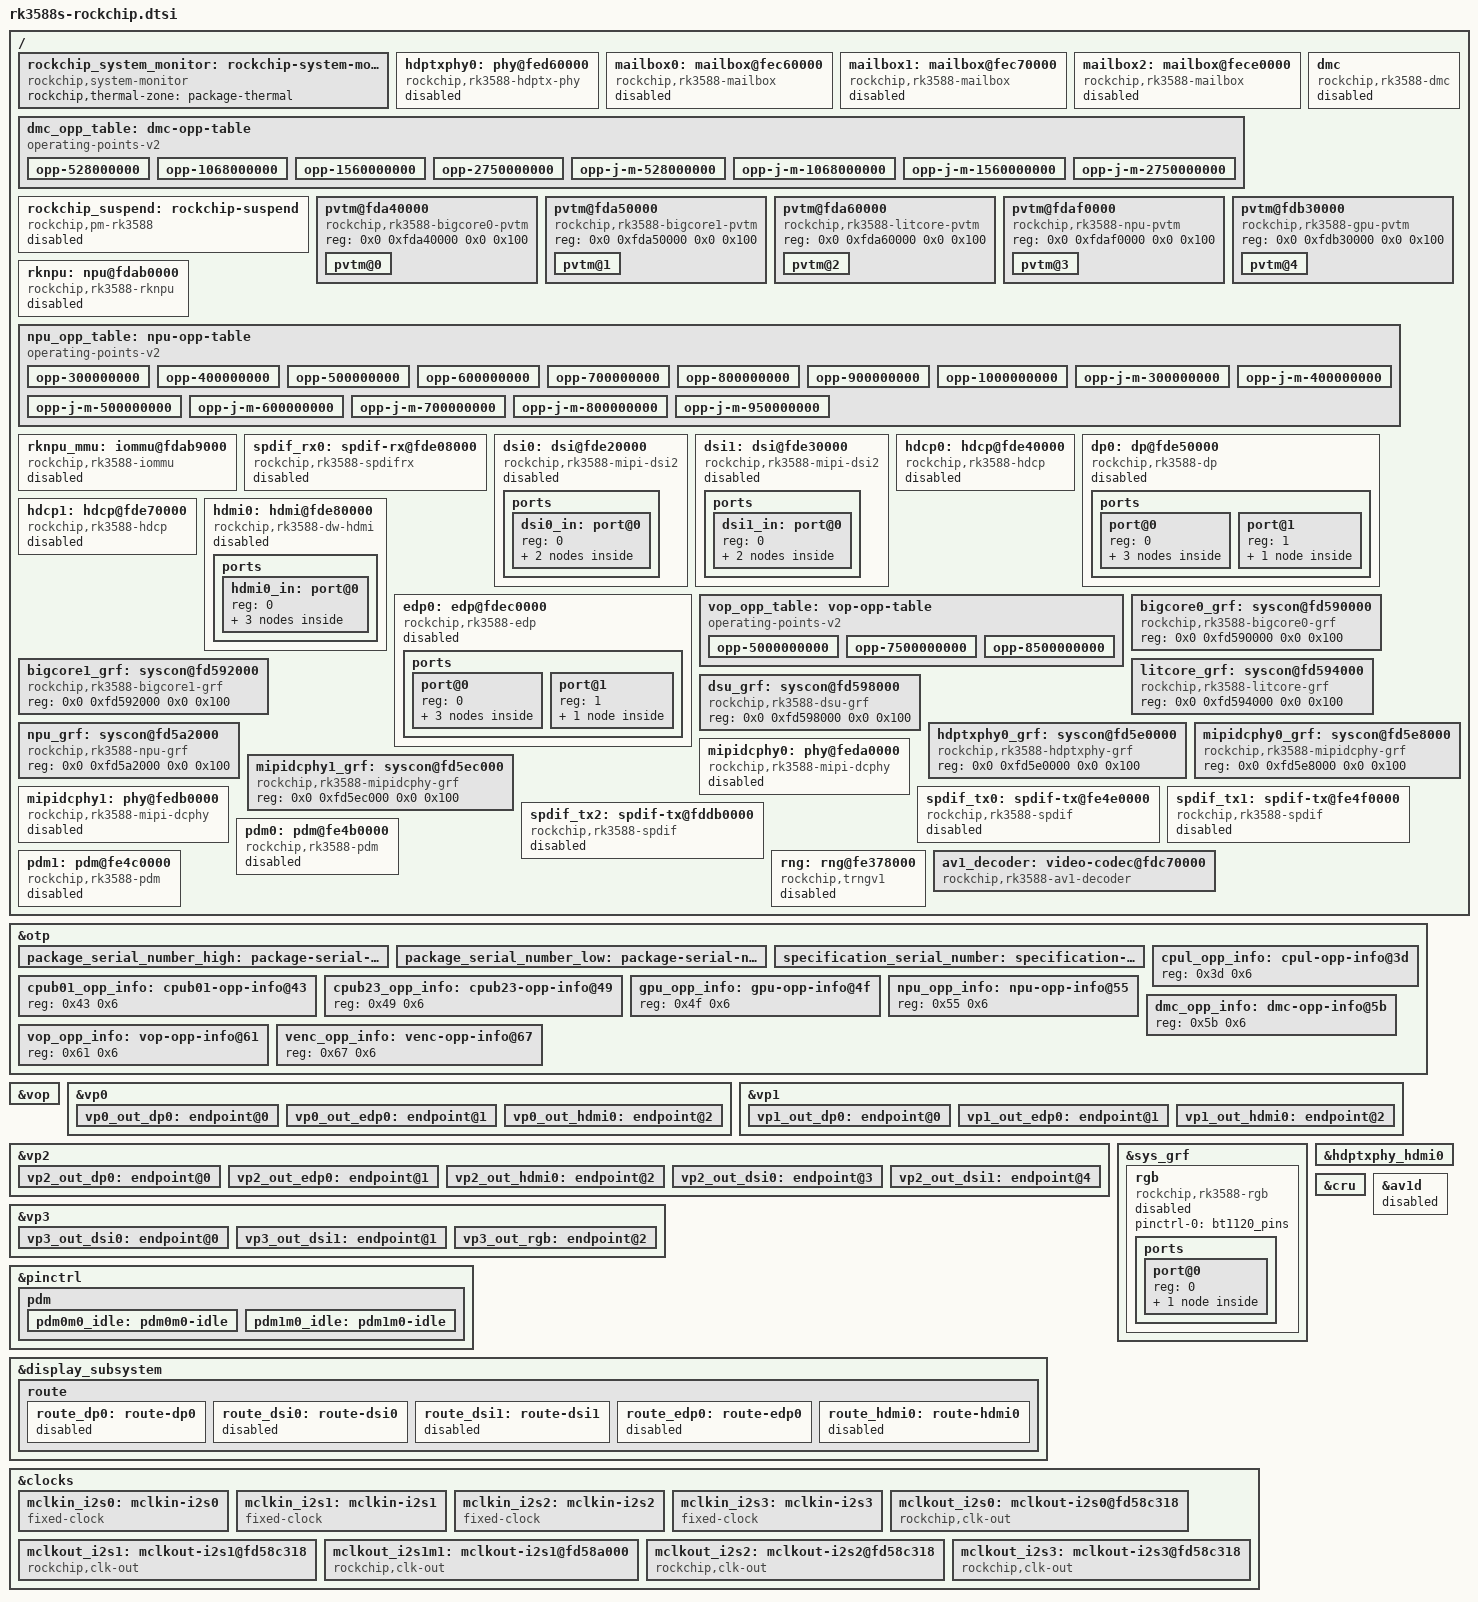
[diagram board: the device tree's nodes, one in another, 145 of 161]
// SPDX-License-Identifier: (GPL-2.0+ OR MIT)

#include <dt-bindings/suspend/rockchip-rk3588.h>
#include <dt-bindings/soc/rockchip-system-status.h>
/ {

  rockchip_system_monitor: rockchip-system-monitor {
    compatible = "rockchip,system-monitor";

    rockchip,thermal-zone = "package-thermal";
  };

  hdptxphy0: phy@fed60000 {
    compatible = "rockchip,rk3588-hdptx-phy";
    reg = <0x0 0xfed60000 0x0 0x2000>;
    clocks = <&cru CLK_USB2PHY_HDPTXRXPHY_REF>, <&cru PCLK_HDPTX0>;
    clock-names = "ref", "apb";
    resets = <&cru SRST_P_HDPTX0>, <&cru SRST_HDPTX0_INIT>,
       <&cru SRST_HDPTX0_CMN>, <&cru SRST_HDPTX0_LANE>;
    reset-names = "apb", "init", "cmn", "lane";
    rockchip,grf = <&hdptxphy0_grf>;
    #phy-cells = <0>;
    status = "disabled";
  };

  mailbox0: mailbox@fec60000 {
    compatible = "rockchip,rk3588-mailbox",
           "rockchip,rk3368-mailbox";
    reg = <0x0 0xfec60000 0x0 0x200>;
    interrupts = <GIC_SPI 61 IRQ_TYPE_LEVEL_HIGH 0>,
           <GIC_SPI 62 IRQ_TYPE_LEVEL_HIGH 0>,
           <GIC_SPI 63 IRQ_TYPE_LEVEL_HIGH 0>,
           <GIC_SPI 64 IRQ_TYPE_LEVEL_HIGH 0>;
    clocks = <&cru PCLK_MAILBOX0>;
    clock-names = "pclk_mailbox";
    #mbox-cells = <1>;
    status = "disabled";
  };

  mailbox1: mailbox@fec70000 {
    compatible = "rockchip,rk3588-mailbox",
           "rockchip,rk3368-mailbox";
    reg = <0x0 0xfec70000 0x0 0x200>;
    interrupts = <GIC_SPI 69 IRQ_TYPE_LEVEL_HIGH 0>,
           <GIC_SPI 70 IRQ_TYPE_LEVEL_HIGH 0>,
           <GIC_SPI 71 IRQ_TYPE_LEVEL_HIGH 0>,
           <GIC_SPI 72 IRQ_TYPE_LEVEL_HIGH 0>;
    clocks = <&cru PCLK_MAILBOX1>;
    clock-names = "pclk_mailbox";
    #mbox-cells = <1>;
    status = "disabled";
  };

  mailbox2: mailbox@fece0000 {
    compatible = "rockchip,rk3588-mailbox",
           "rockchip,rk3368-mailbox";
    reg = <0x0 0xfece0000 0x0 0x200>;
    interrupts = <GIC_SPI 77 IRQ_TYPE_LEVEL_HIGH 0>,
           <GIC_SPI 78 IRQ_TYPE_LEVEL_HIGH 0>,
           <GIC_SPI 79 IRQ_TYPE_LEVEL_HIGH 0>,
           <GIC_SPI 80 IRQ_TYPE_LEVEL_HIGH 0>;
    clocks = <&cru PCLK_MAILBOX2>;
    clock-names = "pclk_mailbox";
    #mbox-cells = <1>;
    status = "disabled";
  };

  dmc: dmc {
    compatible = "rockchip,rk3588-dmc";
    interrupts = <GIC_SPI 73 IRQ_TYPE_LEVEL_HIGH 0>;
    interrupt-names = "complete";
    devfreq-events = <&dfi>;
    clocks = <&scmi_clk 4>;
    clock-names = "dmc_clk";
    operating-points-v2 = <&dmc_opp_table>;
    upthreshold = <40>;
    downdifferential = <20>;
    system-status-level = <
      /*system status         freq level*/
      SYS_STATUS_NORMAL       DMC_FREQ_LEVEL_MID_HIGH
      SYS_STATUS_REBOOT       DMC_FREQ_LEVEL_HIGH
      SYS_STATUS_SUSPEND      DMC_FREQ_LEVEL_LOW
      SYS_STATUS_VIDEO_4K     DMC_FREQ_LEVEL_MID_HIGH
      SYS_STATUS_VIDEO_4K_10B DMC_FREQ_LEVEL_MID_HIGH
      SYS_STATUS_VIDEO_SVEP   DMC_FREQ_LEVEL_MID_HIGH
      SYS_STATUS_BOOST        DMC_FREQ_LEVEL_HIGH
      SYS_STATUS_ISP          DMC_FREQ_LEVEL_HIGH
      SYS_STATUS_PERFORMANCE  DMC_FREQ_LEVEL_HIGH
      SYS_STATUS_DUALVIEW     DMC_FREQ_LEVEL_HIGH
      SYS_STATUS_HDMIRX       DMC_FREQ_LEVEL_HIGH
      SYS_STATUS_DEEP_SUSPEND DMC_FREQ_LEVEL_HIGH
    >;
    auto-freq-en = <1>;
    status = "disabled";
  };

  dmc_opp_table: dmc-opp-table {
    compatible = "operating-points-v2";

    nvmem-cells = <&log_leakage>, <&dmc_opp_info>, <&specification_serial_number>;
    nvmem-cell-names = "leakage", "opp-info", "specification_serial_number";
    rockchip,supported-hw;

    rockchip,leakage-voltage-sel = <
      1 31  0
      32  44  1
      45  57  2
      58  254 3
    >;
    rockchip,temp-hysteresis = <5000>;
    rockchip,low-temp = <15000>;
    rockchip,low-temp-min-volt = <750000>;

    /* RK3588 dmc OPPs */
    opp-528000000 {
      opp-supported-hw = <0xf9 0xffff>;
      opp-hz = /bits/ 64 <528000000>;
      opp-microvolt = <675000 675000 875000>,
          <725000 725000 800000>;
      opp-microvolt-L1 = <675000 675000 875000>,
             <700000 700000 800000>;
      opp-microvolt-L2 = <675000 675000 875000>,
             <687500 687500 800000>;
      opp-microvolt-L3 = <675000 675000 875000>,
             <675000 675000 800000>;
    };
    opp-1068000000 {
      opp-supported-hw = <0xf9 0xffff>;
      opp-hz = /bits/ 64 <1068000000>;
      opp-microvolt = <725000 725000 875000>,
          <737500 737500 800000>;
      opp-microvolt-L1 = <700000 700000 875000>,
             <712500 712500 800000>;
      opp-microvolt-L2 = <675000 675000 875000>,
             <700000 700000 800000>;
      opp-microvolt-L3 = <675000 675000 875000>,
             <687500 687500 800000>;
    };
    opp-1560000000 {
      opp-supported-hw = <0xf9 0xffff>;
      opp-hz = /bits/ 64 <1560000000>;
      opp-microvolt = <800000 800000 875000>,
          <750000 750000 800000>;
      opp-microvolt-L1 = <775000 775000 875000>,
             <725000 725000 800000>;
      opp-microvolt-L2 = <750000 750000 875000>,
             <712500 712500 800000>;
      opp-microvolt-L3 = <725000 725000 875000>,
             <700000 700000 800000>;
    };
    opp-2750000000 {
      opp-supported-hw = <0xf9 0xffff>;
      opp-hz = /bits/ 64 <2750000000>;
      opp-microvolt = <875000 875000 875000>,
          <750000 750000 800000>;
      opp-microvolt-L1 = <850000 850000 875000>,
             <750000 750000 800000>;
      opp-microvolt-L2 = <837500 837500 875000>,
             <725000 725000 800000>;
      opp-microvolt-L3 = <825000 820000 875000>,
             <700000 700000 800000>;
    };
    /* RK3588J/M dmc OPPs */
    opp-j-m-528000000 {
      opp-supported-hw = <0x06 0xffff>;
      opp-hz = /bits/ 64 <528000000>;
      opp-microvolt = <750000 750000 875000>,
          <750000 750000 800000>;
    };
    opp-j-m-1068000000 {
      opp-supported-hw = <0x06 0xffff>;
      opp-hz = /bits/ 64 <1068000000>;
      opp-microvolt = <750000 750000 875000>,
          <750000 750000 800000>;
    };
    opp-j-m-1560000000 {
      opp-supported-hw = <0x06 0xffff>;
      opp-hz = /bits/ 64 <1560000000>;
      opp-microvolt = <800000 800000 875000>,
          <750000 750000 800000>;
      opp-microvolt-L1 = <775000 775000 875000>,
             <750000 750000 800000>;
      opp-microvolt-L2 = <750000 750000 875000>,
             <750000 750000 800000>;
      opp-microvolt-L3 = <750000 750000 875000>,
             <750000 750000 800000>;
    };
    opp-j-m-2750000000 {
      opp-supported-hw = <0x06 0xffff>;
      opp-hz = /bits/ 64 <2750000000>;
      opp-microvolt = <875000 875000 875000>,
          <750000 750000 800000>;
      opp-microvolt-L1 = <850000 850000 875000>,
             <750000 750000 800000>;
      opp-microvolt-L2 = <837500 837500 875000>,
             <750000 750000 800000>;
      opp-microvolt-L3 = <825000 820000 875000>,
             <750000 750000 800000>;
    };
  };

  rockchip_suspend: rockchip-suspend {
    compatible = "rockchip,pm-rk3588";
    status = "disabled";
    rockchip,sleep-debug-en = <0>;
    rockchip,sleep-mode-config = <
      (0
      | RKPM_SLP_ARMOFF_LOGOFF
      | RKPM_SLP_PMU_PMUALIVE_32K
      | RKPM_SLP_PMU_DIS_OSC
      | RKPM_SLP_32K_EXT
      )
    >;
    rockchip,wakeup-config = <
      (0
      | RKPM_GPIO_WKUP_EN
      )
    >;
    power-domains = <&power RK3588_PD_USB>;
  };

  pvtm@fda40000 {
    compatible = "rockchip,rk3588-bigcore0-pvtm";
    reg = <0x0 0xfda40000 0x0 0x100>;
    #address-cells = <1>;
    #size-cells = <0>;
    pvtm@0 {
      reg = <0>;
      clocks = <&cru CLK_BIGCORE0_PVTM>, <&cru PCLK_BIGCORE0_PVTM>;
      clock-names = "clk", "pclk";
    };
  };

  pvtm@fda50000 {
    compatible = "rockchip,rk3588-bigcore1-pvtm";
    reg = <0x0 0xfda50000 0x0 0x100>;
    #address-cells = <1>;
    #size-cells = <0>;
    pvtm@1 {
      reg = <1>;
      clocks = <&cru CLK_BIGCORE1_PVTM>, <&cru PCLK_BIGCORE1_PVTM>;
      clock-names = "clk", "pclk";
    };
  };

  pvtm@fda60000 {
    compatible = "rockchip,rk3588-litcore-pvtm";
    reg = <0x0 0xfda60000 0x0 0x100>;
    #address-cells = <1>;
    #size-cells = <0>;
    pvtm@2 {
      reg = <2>;
      clocks = <&cru CLK_LITCORE_PVTM>, <&cru PCLK_LITCORE_PVTM>;
      clock-names = "clk", "pclk";
    };
  };

  pvtm@fdaf0000 {
    compatible = "rockchip,rk3588-npu-pvtm";
    reg = <0x0 0xfdaf0000 0x0 0x100>;
    #address-cells = <1>;
    #size-cells = <0>;
    pvtm@3 {
      reg = <3>;
      clocks = <&cru CLK_NPU_PVTM>, <&cru PCLK_NPU_PVTM>;
      clock-names = "clk", "pclk";
      resets = <&cru SRST_NPU_PVTM>, <&cru SRST_P_NPU_PVTM>;
      reset-names = "rts", "rst-p";
    };
  };

  pvtm@fdb30000 {
    compatible = "rockchip,rk3588-gpu-pvtm";
    reg = <0x0 0xfdb30000 0x0 0x100>;
    #address-cells = <1>;
    #size-cells = <0>;
    pvtm@4 {
      reg = <4>;
      clocks = <&cru CLK_GPU_PVTM>;
      clock-names = "clk";
      resets = <&cru SRST_GPU_PVTM>, <&cru SRST_P_GPU_PVTM>;
      reset-names = "rts", "rst-p";
    };
  };

  rknpu: npu@fdab0000 {
    compatible = "rockchip,rk3588-rknpu";
    reg = <0x0 0xfdab0000 0x0 0x10000>,
          <0x0 0xfdac0000 0x0 0x10000>,
          <0x0 0xfdad0000 0x0 0x10000>;
    interrupts = <GIC_SPI 110 IRQ_TYPE_LEVEL_HIGH 0>,
           <GIC_SPI 111 IRQ_TYPE_LEVEL_HIGH 0>,
           <GIC_SPI 112 IRQ_TYPE_LEVEL_HIGH 0>;
    interrupt-names = "npu0_irq", "npu1_irq", "npu2_irq";
    clocks = <&scmi_clk SCMI_CLK_NPU>, <&cru ACLK_NPU0>,
       <&cru ACLK_NPU1>, <&cru ACLK_NPU2>,
       <&cru HCLK_NPU0>, <&cru HCLK_NPU1>,
       <&cru HCLK_NPU2>, <&cru PCLK_NPU_ROOT>;
    clock-names = "clk_npu", "aclk0",
            "aclk1", "aclk2",
            "hclk0", "hclk1",
            "hclk2", "pclk";
    assigned-clocks = <&scmi_clk SCMI_CLK_NPU>;
    assigned-clock-rates = <200000000>;
    resets = <&cru SRST_A_RKNN0>, <&cru SRST_A_RKNN1>, <&cru SRST_A_RKNN2>,
       <&cru SRST_H_RKNN0>, <&cru SRST_H_RKNN1>, <&cru SRST_H_RKNN2>;
    reset-names = "srst_a0", "srst_a1", "srst_a2",
            "srst_h0", "srst_h1", "srst_h2";
    power-domains = <&power RK3588_PD_NPUTOP>,
        <&power RK3588_PD_NPU1>,
        <&power RK3588_PD_NPU2>;
    power-domain-names = "npu0", "npu1", "npu2";
    operating-points-v2 = <&npu_opp_table>;
    iommus = <&rknpu_mmu>;
    status = "disabled";
  };

  npu_opp_table: npu-opp-table {
    compatible = "operating-points-v2";

    nvmem-cells = <&npu_leakage>, <&npu_opp_info>, <&specification_serial_number>;
    nvmem-cell-names = "leakage", "opp-info", "specification_serial_number";
    rockchip,supported-hw;

    rockchip,pvtm-hw = <0x06>;
    rockchip,pvtm-voltage-sel-hw = <
      0 799 0
      800 819 1
      820 844 2
      845 869 3
      870 894 4
      895 9999  5
    >;
    rockchip,pvtm-voltage-sel = <
      0 815 0
      816 835 1
      836 860 2
      861 885 3
      886 910 4
      911 9999  5
    >;
    rockchip,pvtm-pvtpll;
    rockchip,pvtm-offset = <0x50>;
    rockchip,pvtm-sample-time = <1100>;
    rockchip,pvtm-freq = <800000>;
    rockchip,pvtm-volt = <750000>;
    rockchip,pvtm-ref-temp = <25>;
    rockchip,pvtm-temp-prop = <(-113) (-113)>;
    rockchip,pvtm-thermal-zone = "npu-thermal";

    rockchip,opp-clocks = <&cru PCLK_NPU_GRF>, <&cru HCLK_NPU_ROOT>;
    rockchip,grf = <&npu_grf>;
    volt-mem-read-margin = <
      855000  1
      765000  2
      675000  3
      495000  4
    >;
    low-volt-mem-read-margin = <4>;
    intermediate-threshold-freq = <500000>; /* KHz*/
    rockchip,init-freq = <1000000>;   /* KHz */

    rockchip,temp-hysteresis = <5000>;
    rockchip,low-temp = <15000>;
    rockchip,low-temp-min-volt = <750000>;
    rockchip,high-temp = <85000>;
    rockchip,high-temp-max-freq = <800000>;

    /* RK3588 npu OPPs */
    opp-300000000 {
      opp-supported-hw = <0xf9 0xffff>;
      opp-hz = /bits/ 64 <300000000>;
      opp-microvolt = <700000 700000 850000>,
          <700000 700000 850000>;
      opp-microvolt-L1 = <687500 687500 850000>,
             <687500 687500 850000>;
      opp-microvolt-L2 = <675000 675000 850000>,
             <675000 675000 850000>;
      opp-microvolt-L3 = <675000 675000 850000>,
             <675000 675000 850000>;
      opp-microvolt-L4 = <675000 675000 850000>,
             <675000 675000 850000>;
      opp-microvolt-L5 = <675000 675000 850000>,
             <675000 675000 850000>;
    };
	  opp-400000000 {
      opp-supported-hw = <0xf9 0xffff>;
      opp-hz = /bits/ 64 <400000000>;
      opp-microvolt = <700000 700000 850000>,
          <700000 700000 850000>;
      opp-microvolt-L1 = <687500 687500 850000>,
             <687500 687500 850000>;
      opp-microvolt-L2 = <675000 675000 850000>,
             <675000 675000 850000>;
      opp-microvolt-L3 = <675000 675000 850000>,
             <675000 675000 850000>;
      opp-microvolt-L4 = <675000 675000 850000>,
             <675000 675000 850000>;
      opp-microvolt-L5 = <675000 675000 850000>,
             <675000 675000 850000>;
    };
    opp-500000000 {
      opp-supported-hw = <0xf9 0xffff>;
      opp-hz = /bits/ 64 <500000000>;
      opp-microvolt = <700000 700000 850000>,
          <700000 700000 850000>;
      opp-microvolt-L1 = <687500 687500 850000>,
             <687500 687500 850000>;
      opp-microvolt-L2 = <675000 675000 850000>,
             <675000 675000 850000>;
      opp-microvolt-L3 = <675000 675000 850000>,
             <675000 675000 850000>;
      opp-microvolt-L4 = <675000 675000 850000>,
             <675000 675000 850000>;
      opp-microvolt-L5 = <675000 675000 850000>,
             <675000 675000 850000>;
    };
    opp-600000000 {
      opp-supported-hw = <0xf9 0xffff>;
      opp-hz = /bits/ 64 <600000000>;
      opp-microvolt = <700000 700000 850000>,
          <700000 700000 850000>;
      opp-microvolt-L1 = <687500 687500 850000>,
             <687500 687500 850000>;
      opp-microvolt-L2 = <675000 675000 850000>,
             <675000 675000 850000>;
      opp-microvolt-L3 = <675000 675000 850000>,
             <675000 675000 850000>;
      opp-microvolt-L4 = <675000 675000 850000>,
             <675000 675000 850000>;
      opp-microvolt-L5 = <675000 675000 850000>,
             <675000 675000 850000>;
    };
    opp-700000000 {
      opp-supported-hw = <0xf9 0xffff>;
      opp-hz = /bits/ 64 <700000000>;
      opp-microvolt = <700000 700000 850000>,
          <700000 700000 850000>;
      opp-microvolt-L3 = <687500 687500 850000>,
             <687500 687500 850000>;
      opp-microvolt-L4 = <675000 675000 850000>,
             <675000 675000 850000>;
      opp-microvolt-L5 = <675000 675000 850000>,
             <675000 675000 850000>;
    };
    opp-800000000 {
      opp-supported-hw = <0xf9 0xffff>;
      opp-hz = /bits/ 64 <800000000>;
      opp-microvolt = <750000 750000 850000>,
          <750000 750000 850000>;
      opp-microvolt-L2 = <737500 737500 850000>,
             <737500 737500 850000>;
      opp-microvolt-L3 = <725000 725000 850000>,
             <725000 725000 850000>;
      opp-microvolt-L4 = <712500 712500 850000>,
             <712500 712500 850000>;
      opp-microvolt-L5 = <700000 700000 850000>,
             <700000 700000 850000>;
    };
		opp-900000000 {
      opp-supported-hw = <0xf9 0xffff>;
      opp-hz = /bits/ 64 <900000000>;
      opp-microvolt = <800000 800000 850000>,
          <800000 800000 850000>;
      opp-microvolt-L1 = <787500 787500 850000>,
             <787500 787500 850000>;
      opp-microvolt-L2 = <775000 775000 850000>,
             <775000 775000 850000>;
      opp-microvolt-L3 = <762500 762500 850000>,
             <762500 762500 850000>;
      opp-microvolt-L4 = <750000 750000 850000>,
             <750000 750000 850000>;
      opp-microvolt-L5 = <737500 737500 850000>,
             <737500 737500 850000>;
    };
    opp-1000000000 {
      opp-supported-hw = <0xf9 0xffff>;
      opp-hz = /bits/ 64 <1000000000>;
      opp-microvolt = <850000 850000 850000>,
          <850000 850000 850000>;
      opp-microvolt-L1 = <837500 837500 850000>,
             <837500 837500 850000>;
      opp-microvolt-L2 = <825000 825000 850000>,
             <825000 825000 850000>;
      opp-microvolt-L3 = <812500 812500 850000>,
             <812500 812500 850000>;
      opp-microvolt-L4 = <800000 800000 850000>,
             <800000 800000 850000>;
      opp-microvolt-L5 = <787500 787500 850000>,
             <787500 787500 850000>;
    };

    /* RK3588J/M npu OPPs */
    opp-j-m-300000000 {
      opp-supported-hw = <0x06 0xffff>;
      opp-hz = /bits/ 64 <300000000>;
      opp-microvolt = <750000 750000 850000>,
          <750000 750000 850000>;
    };
    opp-j-m-400000000 {
      opp-supported-hw = <0x06 0xffff>;
      opp-hz = /bits/ 64 <400000000>;
      opp-microvolt = <750000 750000 850000>,
          <750000 750000 850000>;
    };
    opp-j-m-500000000 {
      opp-supported-hw = <0x06 0xffff>;
      opp-hz = /bits/ 64 <500000000>;
      opp-microvolt = <750000 750000 850000>,
          <750000 750000 850000>;
    };
    opp-j-m-600000000 {
      opp-supported-hw = <0x06 0xffff>;
      opp-hz = /bits/ 64 <600000000>;
      opp-microvolt = <750000 750000 850000>,
          <750000 750000 850000>;
    };
    opp-j-m-700000000 {
      opp-supported-hw = <0x06 0xffff>;
      opp-hz = /bits/ 64 <700000000>;
      opp-microvolt = <750000 750000 850000>,
          <750000 750000 850000>;
    };
    opp-j-m-800000000 {
      opp-supported-hw = <0x06 0xffff>;
      opp-hz = /bits/ 64 <800000000>;
      opp-microvolt = <750000 750000 850000>,
          <750000 750000 850000>;
    };
		opp-j-m-950000000 {
      opp-supported-hw = <0x06 0xffff>;
      opp-hz = /bits/ 64 <950000000>;
      opp-microvolt = <837500 837500 850000>,
          <837500 837500 850000>;
      opp-microvolt-L1 = <825000 825000 850000>,
             <825000 825000 850000>;
      opp-microvolt-L2 = <812500 812500 850000>,
             <812500 812500 850000>;
      opp-microvolt-L3 = <800000 800000 850000>,
             <800000 800000 850000>;
      opp-microvolt-L4 = <787500 787500 850000>,
             <787500 787500 850000>;
      opp-microvolt-L5 = <775000 775000 850000>,
             <775000 775000 850000>;
    };
  };

  rknpu_mmu: iommu@fdab9000 {
    compatible = "rockchip,rk3588-iommu", "rockchip,rk3568-iommu";
    reg = <0x0 0xfdab9000 0x0 0x100>,
          <0x0 0xfdaba000 0x0 0x100>,
          <0x0 0xfdaca000 0x0 0x100>,
          <0x0 0xfdada000 0x0 0x100>;
    interrupts = <GIC_SPI 110 IRQ_TYPE_LEVEL_HIGH 0>,
           <GIC_SPI 111 IRQ_TYPE_LEVEL_HIGH 0>,
           <GIC_SPI 112 IRQ_TYPE_LEVEL_HIGH 0>;
    interrupt-names = "npu0_mmu", "npu1_mmu", "npu2_mmu";
    clocks = <&cru ACLK_NPU0>, <&cru ACLK_NPU1>, <&cru ACLK_NPU2>,
       <&cru HCLK_NPU0>, <&cru HCLK_NPU1>, <&cru HCLK_NPU2>;
    clock-names = "aclk0", "aclk1", "aclk2",
            "iface0", "iface1", "iface2";
    #iommu-cells = <0>;
    status = "disabled";
  };

  spdif_rx0: spdif-rx@fde08000 {
    compatible = "rockchip,rk3588-spdifrx", "rockchip,rk3308-spdifrx";
    reg = <0x0 0xfde08000 0x0 0x1000>;
    interrupts = <GIC_SPI 199 IRQ_TYPE_LEVEL_HIGH 0>;
    clocks = <&cru MCLK_SPDIFRX0>, <&cru HCLK_SPDIFRX0>;
    clock-names = "mclk", "hclk";
    assigned-clocks = <&cru MCLK_SPDIFRX0>;
    assigned-clock-parents = <&cru PLL_AUPLL>;
    dmas = <&dmac0 21>;
    dma-names = "rx";
    power-domains = <&power RK3588_PD_VO1>;
    resets = <&cru SRST_M_SPDIFRX0>;
    reset-names = "spdifrx-m";
    #sound-dai-cells = <0>;
    status = "disabled";
  };

  dsi0: dsi@fde20000 {
    compatible = "rockchip,rk3588-mipi-dsi2";
    reg = <0x0 0xfde20000 0x0 0x10000>;
    interrupts = <GIC_SPI 167 IRQ_TYPE_LEVEL_HIGH 0>;
    clocks = <&cru PCLK_DSIHOST0>, <&cru CLK_DSIHOST0>;
    clock-names = "pclk", "sys_clk";
    resets = <&cru SRST_P_DSIHOST0>;
    reset-names = "apb";
    power-domains = <&power RK3588_PD_VOP>;
    phys = <&mipidcphy0>;
    phy-names = "dcphy";
    rockchip,grf = <&vop_grf>;
    #address-cells = <1>;
    #size-cells = <0>;
    status = "disabled";

    ports {
      #address-cells = <1>;
      #size-cells = <0>;

      dsi0_in: port@0 {
        reg = <0>;
        #address-cells = <1>;
        #size-cells = <0>;

        dsi0_in_vp2: endpoint@0 {
          reg = <0>;
          remote-endpoint = <&vp2_out_dsi0>;
          status = "disabled";
        };

        dsi0_in_vp3: endpoint@1 {
          reg = <1>;
          remote-endpoint = <&vp3_out_dsi0>;
          status = "disabled";
        };
      };
    };
  };

  dsi1: dsi@fde30000 {
    compatible = "rockchip,rk3588-mipi-dsi2";
    reg = <0x0 0xfde30000 0x0 0x10000>;
    interrupts = <GIC_SPI 168 IRQ_TYPE_LEVEL_HIGH 0>;
    clocks = <&cru PCLK_DSIHOST1>, <&cru CLK_DSIHOST1>;
    clock-names = "pclk", "sys_clk";
    resets = <&cru SRST_P_DSIHOST1>;
    reset-names = "apb";
    power-domains = <&power RK3588_PD_VOP>;
    phys = <&mipidcphy1>;
    phy-names = "dcphy";
    rockchip,grf = <&vop_grf>;
    #address-cells = <1>;
    #size-cells = <0>;
    status = "disabled";

    ports {
      #address-cells = <1>;
      #size-cells = <0>;

      dsi1_in: port@0 {
        reg = <0>;
        #address-cells = <1>;
        #size-cells = <0>;

        dsi1_in_vp2: endpoint@0 {
          reg = <0>;
          remote-endpoint = <&vp2_out_dsi1>;
          status = "disabled";
        };

        dsi1_in_vp3: endpoint@1 {
          reg = <1>;
          remote-endpoint = <&vp3_out_dsi1>;
          status = "disabled";
        };
      };
    };
  };

  hdcp0: hdcp@fde40000 {
    compatible = "rockchip,rk3588-hdcp";
    reg = <0x0 0xfde40000 0x0 0x80>;
    interrupts = <GIC_SPI 159 IRQ_TYPE_LEVEL_HIGH 0>;
    clocks = <&cru ACLK_HDCP0>, <&cru PCLK_HDCP0>,
       <&cru HCLK_HDCP0>, <&cru HCLK_HDCP_KEY0>,
       <&cru ACLK_TRNG0>, <&cru PCLK_TRNG0>;
    clock-names = "aclk", "pclk", "hclk", "hclk_key", "aclk_trng", "pclk_trng";
    resets = <&cru SRST_HDCP0>, <&cru SRST_H_HDCP0>,
       <&cru SRST_A_HDCP0>, <&cru SRST_H_HDCP_KEY0>,
       <&cru SRST_P_TRNG0>;
    reset-names = "hdcp", "h_hdcp", "a_hdcp", "hdcp_key", "trng";
    power-domains = <&power RK3588_PD_VO0>;
    rockchip,vo-grf = <&vo0_grf>;
    status = "disabled";
  };

  dp0: dp@fde50000 {
    compatible = "rockchip,rk3588-dp";
    reg = <0x0 0xfde50000 0x0 0x4000>;
    interrupts = <GIC_SPI 161 IRQ_TYPE_LEVEL_HIGH 0>;
    clocks = <&cru PCLK_DP0>, <&cru CLK_AUX16M_0>,
       <&cru MCLK_I2S4_8CH_TX>, <&cru MCLK_SPDIF2_DP0>,
       <&cru HCLK_VO0>, <&cru CLK_DP0>;
    clock-names = "apb", "aux", "i2s", "spdif", "hclk", "hdcp";
    assigned-clocks = <&cru CLK_AUX16M_0>;
    assigned-clock-rates = <16000000>;
    resets = <&cru SRST_DP0>;
    phys = <&usbdp_phy0 PHY_TYPE_DP>;
    power-domains = <&power RK3588_PD_VO0>;
    mode-switch;
    #sound-dai-cells = <1>;
    status = "disabled";

    ports {
      #address-cells = <1>;
      #size-cells = <0>;

      port@0 {
        reg = <0>;
        #address-cells = <1>;
        #size-cells = <0>;

        dp0_in_vp0: endpoint@0 {
          reg = <0>;
          remote-endpoint = <&vp0_out_dp0>;
          status = "disabled";
        };

        dp0_in_vp1: endpoint@1 {
          reg = <1>;
          remote-endpoint = <&vp1_out_dp0>;
          status = "disabled";
        };

        dp0_in_vp2: endpoint@2 {
          reg = <2>;
          remote-endpoint = <&vp2_out_dp0>;
          status = "disabled";
        };
      };

      port@1 {
        reg = <1>;

        dp0_out: endpoint { };
      };
    };
  };

  hdcp1: hdcp@fde70000 {
    compatible = "rockchip,rk3588-hdcp";
    reg = <0x0 0xfde70000 0x0 0x80>;
    interrupts = <GIC_SPI 160 IRQ_TYPE_LEVEL_HIGH 0>;
    clocks = <&cru ACLK_HDCP1>, <&cru PCLK_HDCP1>,
       <&cru HCLK_HDCP1>, <&cru HCLK_HDCP_KEY1>,
       <&cru ACLK_TRNG1>, <&cru PCLK_TRNG1>;
    clock-names = "aclk", "pclk", "hclk", "hclk_key", "aclk_trng", "pclk_trng";
    resets = <&cru SRST_HDCP1>, <&cru SRST_H_HDCP1>,
       <&cru SRST_A_HDCP1>, <&cru SRST_H_HDCP_KEY1>,
       <&cru SRST_P_TRNG1>;
    reset-names = "hdcp", "h_hdcp", "a_hdcp", "hdcp_key", "trng";
    power-domains = <&power RK3588_PD_VO1>;
    rockchip,vo-grf = <&vo1_grf>;
    status = "disabled";
  };

  hdmi0: hdmi@fde80000 {
    compatible = "rockchip,rk3588-dw-hdmi";
    reg = <0x0 0xfde80000 0x0 0x10000>, <0x0 0xfde90000 0x0 0x10000>;
    interrupts = <GIC_SPI 169 IRQ_TYPE_LEVEL_HIGH 0>,
           <GIC_SPI 170 IRQ_TYPE_LEVEL_HIGH 0>,
           <GIC_SPI 171 IRQ_TYPE_LEVEL_HIGH 0>,
           <GIC_SPI 172 IRQ_TYPE_LEVEL_HIGH 0>,
           <GIC_SPI 360 IRQ_TYPE_LEVEL_HIGH 0>;
    clocks = <&cru PCLK_HDMITX0>,
       <&cru CLK_HDMIHDP0>,
       <&cru CLK_HDMITX0_EARC>,
       <&cru CLK_HDMITX0_REF>,
       <&cru MCLK_I2S5_8CH_TX>,
       <&cru DCLK_VOP0>,
       <&cru DCLK_VOP1>,
       <&cru DCLK_VOP2>,
       <&cru DCLK_VOP3>,
       <&cru HCLK_VO1>,
       <&hdptxphy_hdmi0>;
    clock-names = "pclk",
            "hpd",
            "earc",
            "hdmitx_ref",
            "aud",
            "dclk_vp0",
            "dclk_vp1",
            "dclk_vp2",
            "dclk_vp3",
            "hclk_vo1",
            "link_clk";
    resets = <&cru SRST_HDMITX0_REF>, <&cru SRST_HDMIHDP0>;
    reset-names = "ref", "hdp";
    power-domains = <&power RK3588_PD_VO1>;
    pinctrl-names = "default";
    pinctrl-0 = <&hdmim0_tx0_cec &hdmim0_tx0_hpd &hdmim0_tx0_scl &hdmim0_tx0_sda>;
    reg-io-width = <4>;
    rockchip,grf = <&sys_grf>;
    rockchip,vo1_grf = <&vo1_grf>;
    phys = <&hdptxphy_hdmi0>;
    phy-names = "hdmi";
    #sound-dai-cells = <0>;
    status = "disabled";

		ports {
      #address-cells = <1>;
      #size-cells = <0>;

      hdmi0_in: port@0 {
        reg = <0>;
        #address-cells = <1>;
        #size-cells = <0>;

        hdmi0_in_vp0: endpoint@0 {
          reg = <0>;
          remote-endpoint = <&vp0_out_hdmi0>;
          status = "disabled";
        };

        hdmi0_in_vp1: endpoint@1 {
          reg = <1>;
          remote-endpoint = <&vp1_out_hdmi0>;
          status = "disabled";
        };

        hdmi0_in_vp2: endpoint@2 {
          reg = <2>;
          remote-endpoint = <&vp2_out_hdmi0>;
          status = "disabled";
        };
      };
    };
  };

  edp0: edp@fdec0000 {
    compatible = "rockchip,rk3588-edp";
    reg = <0x0 0xfdec0000 0x0 0x1000>;
    interrupts = <GIC_SPI 163 IRQ_TYPE_LEVEL_HIGH 0>;
    clocks = <&cru CLK_EDP0_24M>, <&cru PCLK_EDP0>,
       <&cru CLK_EDP0_200M>, <&cru HCLK_VO1>;
    clock-names = "dp", "pclk", "spdif", "hclk";
    resets = <&cru SRST_EDP0_24M>, <&cru SRST_P_EDP0>;
    reset-names = "dp", "apb";
    phys = <&hdptxphy0>;
    phy-names = "dp";
    power-domains = <&power RK3588_PD_VO1>;
    rockchip,grf = <&vo1_grf>;
    #sound-dai-cells = <1>;
    status = "disabled";

    ports {
      #address-cells = <1>;
      #size-cells = <0>;

      port@0 {
        reg = <0>;
        #address-cells = <1>;
        #size-cells = <0>;

        edp0_in_vp0: endpoint@0 {
          reg = <0>;
          remote-endpoint = <&vp0_out_edp0>;
          status = "disabled";
        };

        edp0_in_vp1: endpoint@1 {
          reg = <1>;
          remote-endpoint = <&vp1_out_edp0>;
          status = "disabled";
        };

        edp0_in_vp2: endpoint@2 {
          reg = <2>;
          remote-endpoint = <&vp2_out_edp0>;
          status = "disabled";
        };
      };

      port@1 {
        reg = <1>;

        edp0_out: endpoint { };
      };
    };
  };

  vop_opp_table: vop-opp-table {
    compatible = "operating-points-v2";

    nvmem-cells = <&log_leakage>;
    nvmem-cell-names = "leakage";

    rockchip,init-freq = <500000>; /* KHz */

    rockchip,leakage-voltage-sel = <
      1 31  0
      32  44  1
      45  57  2
      58  254 3
    >;

    opp-5000000000 {
      opp-hz = /bits/ 64 <500000000>;
      opp-microvolt = <725000 725000 800000>;
      opp-microvolt-L1 = <700000 700000 800000>;
      opp-microvolt-L2 = <687500 687500 800000>;
      opp-microvolt-L3 = <675000 675000 800000>;
    };
    opp-7500000000 {
      opp-hz = /bits/ 64 <750000000>;
      opp-microvolt = <725000 725000 800000>;
      opp-microvolt-L1 = <700000 700000 800000>;
      opp-microvolt-L2 = <687500 687500 800000>;
      opp-microvolt-L3 = <675000 675000 800000>;
    };
    opp-8500000000 {
      opp-hz = /bits/ 64 <850000000>;
      opp-microvolt = <800000 800000 800000>;
      opp-microvolt-L1 = <775000 775000 800000>;
      opp-microvolt-L2 = <750000 750000 800000>;
      opp-microvolt-L3 = <750000 750000 800000>;
    };
  };

  /* Missing GRF nodes */
  bigcore0_grf: syscon@fd590000 {
    compatible = "rockchip,rk3588-bigcore0-grf", "syscon";
    reg = <0x0 0xfd590000 0x0 0x100>;
  };

  bigcore1_grf: syscon@fd592000 {
    compatible = "rockchip,rk3588-bigcore1-grf", "syscon";
    reg = <0x0 0xfd592000 0x0 0x100>;
  };

  litcore_grf: syscon@fd594000 {
    compatible = "rockchip,rk3588-litcore-grf", "syscon";
    reg = <0x0 0xfd594000 0x0 0x100>;
  };

  dsu_grf: syscon@fd598000 {
    compatible = "rockchip,rk3588-dsu-grf", "syscon";
    reg = <0x0 0xfd598000 0x0 0x100>;
  };

  npu_grf: syscon@fd5a2000 {
    compatible = "rockchip,rk3588-npu-grf", "syscon";
    reg = <0x0 0xfd5a2000 0x0 0x100>;
  };

  hdptxphy0_grf: syscon@fd5e0000 {
    compatible = "rockchip,rk3588-hdptxphy-grf", "syscon";
    reg = <0x0 0xfd5e0000 0x0 0x100>;
  };

  mipidcphy0_grf: syscon@fd5e8000 {
    compatible = "rockchip,rk3588-mipidcphy-grf", "syscon";
    reg = <0x0 0xfd5e8000 0x0 0x100>;
  };

  mipidcphy1_grf: syscon@fd5ec000 {
    compatible = "rockchip,rk3588-mipidcphy-grf", "syscon";
    reg = <0x0 0xfd5ec000 0x0 0x100>;
  };

  /* Updated to use existing aliases from rk3588-base.dtsi */
  /* Removed duplicate phy@fed60000 and phy@fed80000 nodes - they exist in rk3588-base.dtsi */

  mipidcphy0: phy@feda0000 {
    compatible = "rockchip,rk3588-mipi-dcphy";
    reg = <0x0 0xfeda0000 0x0 0x10000>;
    rockchip,grf = <&mipidcphy0_grf>;
    clocks = <&cru PCLK_MIPI_DCPHY0>,
       <&cru CLK_USBDPPHY_MIPIDCPPHY_REF>;
    clock-names = "pclk", "ref";
    resets = <&cru SRST_M_MIPI_DCPHY0>,
       <&cru SRST_P_MIPI_DCPHY0>,
       <&cru SRST_P_MIPI_DCPHY0_GRF>,
       <&cru SRST_S_MIPI_DCPHY0>;
    reset-names = "m_phy", "apb", "grf", "s_phy";
    #phy-cells = <0>;
    status = "disabled";
  };

  mipidcphy1: phy@fedb0000 {
    compatible = "rockchip,rk3588-mipi-dcphy";
    reg = <0x0 0xfedb0000 0x0 0x10000>;
    rockchip,grf = <&mipidcphy1_grf>;
    clocks = <&cru PCLK_MIPI_DCPHY1>,
       <&cru CLK_USBDPPHY_MIPIDCPPHY_REF>;
    clock-names = "pclk", "ref";
    resets = <&cru SRST_M_MIPI_DCPHY1>,
       <&cru SRST_P_MIPI_DCPHY1>,
       <&cru SRST_P_MIPI_DCPHY1_GRF>,
       <&cru SRST_S_MIPI_DCPHY1>;
    reset-names = "m_phy", "apb", "grf", "s_phy";
    #phy-cells = <0>;
    status = "disabled";
  };

  spdif_tx0: spdif-tx@fe4e0000 {
    compatible = "rockchip,rk3588-spdif", "rockchip,rk3568-spdif";
    reg = <0x0 0xfe4e0000 0x0 0x1000>;
    interrupts = <GIC_SPI 193 IRQ_TYPE_LEVEL_HIGH 0>;
    dmas = <&dmac0 5>;
    dma-names = "tx";
    clock-names = "mclk", "hclk";
    clocks = <&cru MCLK_SPDIF0>, <&cru HCLK_SPDIF0>;
    assigned-clocks = <&cru CLK_SPDIF0_SRC>;
    assigned-clock-parents = <&cru PLL_AUPLL>;
    power-domains = <&power RK3588_PD_AUDIO>;
    pinctrl-names = "default";
    pinctrl-0 = <&spdif0m0_tx>;
    #sound-dai-cells = <0>;
    status = "disabled";
  };

  spdif_tx1: spdif-tx@fe4f0000 {
    compatible = "rockchip,rk3588-spdif", "rockchip,rk3568-spdif";
    reg = <0x0 0xfe4f0000 0x0 0x1000>;
    interrupts = <GIC_SPI 194 IRQ_TYPE_LEVEL_HIGH 0>;
    dmas = <&dmac1 5>;
    dma-names = "tx";
    clock-names = "mclk", "hclk";
    clocks = <&cru MCLK_SPDIF1>, <&cru HCLK_SPDIF1>;
    assigned-clocks = <&cru CLK_SPDIF1_SRC>;
    assigned-clock-parents = <&cru PLL_AUPLL>;
    power-domains = <&power RK3588_PD_AUDIO>;
    pinctrl-names = "default";
    pinctrl-0 = <&spdif1m0_tx>;
    #sound-dai-cells = <0>;
    status = "disabled";
  };

  spdif_tx2: spdif-tx@fddb0000 {
    compatible = "rockchip,rk3588-spdif", "rockchip,rk3568-spdif";
    reg = <0x0 0xfddb0000 0x0 0x1000>;
    interrupts = <GIC_SPI 195 IRQ_TYPE_LEVEL_HIGH 0>;
    dmas = <&dmac1 6>;
    dma-names = "tx";
    clock-names = "mclk", "hclk";
    clocks = <&cru MCLK_SPDIF2>, <&cru HCLK_SPDIF2_DP0>;
    assigned-clocks = <&cru CLK_SPDIF2_DP0_SRC>;
    assigned-clock-parents = <&cru PLL_AUPLL>;
    power-domains = <&power RK3588_PD_VO0>;
    #sound-dai-cells = <0>;
    status = "disabled";
  };

  spdif_rx0: spdif-rx@fde08000 {
    compatible = "rockchip,rk3588-spdifrx", "rockchip,rk3308-spdifrx";
    reg = <0x0 0xfde08000 0x0 0x1000>;
    interrupts = <GIC_SPI 199 IRQ_TYPE_LEVEL_HIGH 0>;
    clocks = <&cru MCLK_SPDIFRX0>, <&cru HCLK_SPDIFRX0>;
    clock-names = "mclk", "hclk";
    assigned-clocks = <&cru MCLK_SPDIFRX0>;
    assigned-clock-parents = <&cru PLL_AUPLL>;
    dmas = <&dmac0 21>;
    dma-names = "rx";
    power-domains = <&power RK3588_PD_VO1>;
    resets = <&cru SRST_M_SPDIFRX0>;
    reset-names = "spdifrx-m";
    #sound-dai-cells = <0>;
    status = "disabled";
  };

  pdm0: pdm@fe4b0000 {
    compatible = "rockchip,rk3588-pdm";
    reg = <0x0 0xfe4b0000 0x0 0x1000>;
    clocks = <&cru MCLK_PDM0>, <&cru HCLK_PDM0>;
    clock-names = "pdm_clk", "pdm_hclk";
    dmas = <&dmac0 4>;
    dma-names = "rx";
    pinctrl-names = "default", "idle", "clk";
    pinctrl-0 = <&pdm0m0_sdi0
           &pdm0m0_sdi1
           &pdm0m0_sdi2
           &pdm0m0_sdi3>;
    pinctrl-1 = <&pdm0m0_idle>;
    pinctrl-2 = <&pdm0m0_clk
           &pdm0m0_clk1>;
    #sound-dai-cells = <0>;
    status = "disabled";
  };

  pdm1: pdm@fe4c0000 {
    compatible = "rockchip,rk3588-pdm";
    reg = <0x0 0xfe4c0000 0x0 0x1000>;
    clocks = <&cru MCLK_PDM1>, <&cru HCLK_PDM1>;
    clock-names = "pdm_clk", "pdm_hclk";
    assigned-clocks = <&cru MCLK_PDM1>;
    assigned-clock-parents = <&cru PLL_AUPLL>;
    dmas = <&dmac1 4>;
    dma-names = "rx";
    power-domains = <&power RK3588_PD_AUDIO>;
    pinctrl-names = "default", "idle", "clk";
    pinctrl-0 = <&pdm1m0_sdi0
           &pdm1m0_sdi1
           &pdm1m0_sdi2
           &pdm1m0_sdi3>;
    pinctrl-1 = <&pdm1m0_idle>;
    pinctrl-2 = <&pdm1m0_clk
           &pdm1m0_clk1>;
    #sound-dai-cells = <0>;
    status = "disabled";
  };

  rng: rng@fe378000 {
    compatible = "rockchip,trngv1";
    reg = <0x0 0xfe378000 0x0 0x200>;
    interrupts = <GIC_SPI 400 IRQ_TYPE_LEVEL_HIGH 0>;
    clocks = <&scmi_clk SCMI_HCLK_SECURE_NS>;
    clock-names = "hclk_trng";
    resets = <&scmi_reset SRST_H_TRNG_NS>;
    reset-names = "reset";
    status = "disabled";
  };
};

&otp {
    package_serial_number_high: package-serial-number-high@5 {
      reg = <0x05 0x1>;
      bits = <0 1>;
    };
    package_serial_number_low: package-serial-number-low@6 {
      reg = <0x06 0x1>;
      bits = <5 3>;
    };
    specification_serial_number: specification-serial-number@6 {
      reg = <0x06 0x1>;
      bits = <0 5>;
    };
    cpul_opp_info: cpul-opp-info@3d {
      reg = <0x3d 0x6>;
    };
    cpub01_opp_info: cpub01-opp-info@43 {
      reg = <0x43 0x6>;
    };
    cpub23_opp_info: cpub23-opp-info@49 {
      reg = <0x49 0x6>;
    };
    gpu_opp_info: gpu-opp-info@4f {
      reg = <0x4f 0x6>;
    };
    npu_opp_info: npu-opp-info@55 {
      reg = <0x55 0x6>;
    };
    dmc_opp_info: dmc-opp-info@5b {
      reg = <0x5b 0x6>;
    };
    vop_opp_info: vop-opp-info@61 {
      reg = <0x61 0x6>;
    };
    venc_opp_info: venc-opp-info@67 {
      reg = <0x67 0x6>;
    };
};

&vop {
    clocks = <&cru ACLK_VOP>,
       <&cru HCLK_VOP>,
       <&cru DCLK_VOP0>,
       <&cru DCLK_VOP1>,
       <&cru DCLK_VOP2>,
       <&cru DCLK_VOP3>,
       <&cru PCLK_VOP_ROOT>,
       <&cru DCLK_VOP0_SRC>,
       <&cru DCLK_VOP1_SRC>,
       <&cru DCLK_VOP2_SRC>;
    clock-names = "aclk_vop",
            "hclk_vop",
            "dclk_vp0",
            "dclk_vp1",
            "dclk_vp2",
            "dclk_vp3",
            "pclk_vop",
            "dclk_src_vp0",
            "dclk_src_vp1",
            "dclk_src_vp2";
    assigned-clocks = <&cru ACLK_VOP>;
    assigned-clock-rates = <750000000>;
    resets = <&cru SRST_A_VOP>,
       <&cru SRST_H_VOP>,
       <&cru SRST_D_VOP0>,
       <&cru SRST_D_VOP1>,
       <&cru SRST_D_VOP2>,
       <&cru SRST_D_VOP3>;
    reset-names = "axi",
            "ahb",
            "dclk_vp0",
            "dclk_vp1",
            "dclk_vp2",
            "dclk_vp3";
    rockchip,aclk-normal-mode-rates = <500000000>;
    rockchip,aclk-advanced-mode-rates = <750000000>;
    operating-points-v2 = <&vop_opp_table>;
};

&vp0 {
  vp0_out_dp0: endpoint@0 {
    reg = <0>;
    remote-endpoint = <&dp0_in_vp0>;
  };

  vp0_out_edp0: endpoint@1 {
    reg = <1>;
    remote-endpoint = <&edp0_in_vp0>;
  };

  vp0_out_hdmi0: endpoint@2 {
    reg = <2>;
    remote-endpoint = <&hdmi0_in_vp0>;
  };
};

&vp1 {
  vp1_out_dp0: endpoint@0 {
    reg = <0>;
    remote-endpoint = <&dp0_in_vp1>;
  };

  vp1_out_edp0: endpoint@1 {
    reg = <1>;
    remote-endpoint = <&edp0_in_vp1>;
  };

  vp1_out_hdmi0: endpoint@2 {
    reg = <2>;
    remote-endpoint = <&hdmi0_in_vp1>;
  };
};

&vp2 {
  assigned-clocks = <&cru DCLK_VOP2_SRC>;
  assigned-clock-parents = <&cru PLL_V0PLL>;

  vp2_out_dp0: endpoint@0 {
    reg = <0>;
    remote-endpoint = <&dp0_in_vp2>;
  };

  vp2_out_edp0: endpoint@1 {
    reg = <1>;
    remote-endpoint = <&edp0_in_vp2>;
  };

  vp2_out_hdmi0: endpoint@2 {
    reg = <2>;
    remote-endpoint = <&hdmi0_in_vp2>;
  };

  vp2_out_dsi0: endpoint@3 {
    reg = <3>;
    remote-endpoint = <&dsi0_in_vp2>;
  };

  vp2_out_dsi1: endpoint@4 {
    reg = <4>;
    remote-endpoint = <&dsi1_in_vp2>;
  };
};

&sys_grf {
  rgb: rgb {
    compatible = "rockchip,rk3588-rgb";
    pinctrl-names = "default";
    pinctrl-0 = <&bt1120_pins>;
    status = "disabled";

    ports {
      #address-cells = <1>;
      #size-cells = <0>;

      port@0 {
        reg = <0>;
        #address-cells = <1>;
        #size-cells = <0>;

        rgb_in_vp3: endpoint@2 {
          reg = <2>;
          remote-endpoint = <&vp3_out_rgb>;
          status = "disabled";
        };
      };
    };
	};
};

&vp3 {
  vp3_out_dsi0: endpoint@0 {
    reg = <0>;
    remote-endpoint = <&dsi0_in_vp3>;
  };

  vp3_out_dsi1: endpoint@1 {
    reg = <1>;
    remote-endpoint = <&dsi1_in_vp3>;
  };

  vp3_out_rgb: endpoint@2 {
    reg = <2>;
    remote-endpoint = <&rgb_in_vp3>;
  };
};

&pinctrl {
	pdm {
		pdm0m0_idle: pdm0m0-idle {
			rockchip,pins =
				/* pdm0_sdi0_m0 */
				<3 RK_PD2 RK_FUNC_GPIO &pcfg_pull_none>,
				/* pdm0_sdi1_m0 */
				<3 RK_PD3 RK_FUNC_GPIO &pcfg_pull_none>,
				/* pdm0_sdi2_m0 */
				<3 RK_PD4 RK_FUNC_GPIO &pcfg_pull_none>,
				/* pdm0_sdi3_m0 */
				<3 RK_PD5 RK_FUNC_GPIO &pcfg_pull_none>;
		};

		pdm1m0_idle: pdm1m0-idle {
			rockchip,pins =
				/* pdm1_sdi0_m0 */
				<3 RK_PD6 RK_FUNC_GPIO &pcfg_pull_none>,
				/* pdm1_sdi1_m0 */
				<3 RK_PD7 RK_FUNC_GPIO &pcfg_pull_none>,
				/* pdm1_sdi2_m0 */
				<3 RK_PC6 RK_FUNC_GPIO &pcfg_pull_none>,
				/* pdm1_sdi3_m0 */
				<3 RK_PC7 RK_FUNC_GPIO &pcfg_pull_none>;
		};
	};
};

&display_subsystem {
	route {
		route_dp0: route-dp0 {
			status = "disabled";
			logo,uboot = "logo.bmp";
			logo,kernel = "logo_kernel.bmp";
			logo,mode = "center";
			charge_logo,mode = "center";
			connect = <&vp1_out_dp0>;
		};

		route_dsi0: route-dsi0 {
			status = "disabled";
			logo,uboot = "logo.bmp";
			logo,kernel = "logo_kernel.bmp";
			logo,mode = "center";
			charge_logo,mode = "center";
			connect = <&vp3_out_dsi0>;
		};

		route_dsi1: route-dsi1 {
			status = "disabled";
			logo,uboot = "logo.bmp";
			logo,kernel = "logo_kernel.bmp";
			logo,mode = "center";
			charge_logo,mode = "center";
			connect = <&vp3_out_dsi1>;
		};

		route_edp0: route-edp0 {
			status = "disabled";
			logo,uboot = "logo.bmp";
			logo,kernel = "logo_kernel.bmp";
			logo,mode = "center";
			charge_logo,mode = "center";
			connect = <&vp2_out_edp0>;
		};

		route_hdmi0: route-hdmi0 {
			status = "disabled";
			logo,uboot = "logo.bmp";
			logo,kernel = "logo_kernel.bmp";
			logo,mode = "center";
			charge_logo,mode = "center";
			connect = <&vp0_out_hdmi0>;
		};
	};
};

&hdptxphy_hdmi0 {
  #clock-cells = <0>;
};

&cru {
    assigned-clocks =
      <&cru PLL_PPLL>, <&cru PLL_AUPLL>,
      <&cru PLL_NPLL>, <&cru PLL_GPLL>,
      <&cru ACLK_CENTER_ROOT>,
      <&cru HCLK_CENTER_ROOT>, <&cru ACLK_CENTER_LOW_ROOT>,
      <&cru ACLK_TOP_ROOT>, <&cru PCLK_TOP_ROOT>,
      <&cru ACLK_LOW_TOP_ROOT>, <&cru PCLK_PMU0_ROOT>,
      <&cru HCLK_PMU_CM0_ROOT>,
      <&cru ACLK_BUS_ROOT>, <&cru CLK_150M_SRC>,
      <&cru CLK_GPU>, <&cru CLK_SPDIF2_DP0>,
      <&cru CLK_SPDIF5_DP1>, <&cru CLK_HDMIRX_AUD>,
      <&cru DCLK_DECOM>;
    assigned-clock-rates =
      <1100000000>, <786432000>,
      <850000000>, <1188000000>,
      <702000000>,
      <400000000>, <500000000>,
      <750000000>, <100000000>,
      <400000000>, <100000000>,
      <200000000>,
      <375000000>, <150000000>,
      <200000000>, <12000000>,
      <12000000>, <99000000>,
      <20000000>;
};

&clocks {
    mclkin_i2s0: mclkin-i2s0 {
      compatible = "fixed-clock";
      #clock-cells = <0>;
      clock-frequency = <0>;
      clock-output-names = "i2s0_mclkin";
    };

    mclkin_i2s1: mclkin-i2s1 {
      compatible = "fixed-clock";
      #clock-cells = <0>;
      clock-frequency = <0>;
      clock-output-names = "i2s1_mclkin";
    };

		mclkin_i2s2: mclkin-i2s2 {
      compatible = "fixed-clock";
      #clock-cells = <0>;
      clock-frequency = <0>;
      clock-output-names = "i2s2_mclkin";
    };

    mclkin_i2s3: mclkin-i2s3 {
      compatible = "fixed-clock";
      #clock-cells = <0>;
      clock-frequency = <0>;
      clock-output-names = "i2s3_mclkin";
    };

    mclkout_i2s0: mclkout-i2s0@fd58c318 {
      compatible = "rockchip,clk-out";
      reg = <0 0xfd58c318 0 0x4>;
      clocks = <&cru I2S0_8CH_MCLKOUT>;
      #clock-cells = <0>;
      clock-output-names = "i2s0_mclkout_to_io";
      power-domains = <&power RK3588_PD_AUDIO>;
      rockchip,bit-shift = <0>;
      rockchip,bit-set-to-disable;
    };

    mclkout_i2s1: mclkout-i2s1@fd58c318 {
      compatible = "rockchip,clk-out";
      reg = <0 0xfd58c318 0 0x4>;
      clocks = <&cru I2S1_8CH_MCLKOUT>;
      #clock-cells = <0>;
      clock-output-names = "i2s1_mclkout_to_io";
      rockchip,bit-shift = <1>;
      rockchip,bit-set-to-disable;
    };

    mclkout_i2s1m1: mclkout-i2s1@fd58a000 {
      compatible = "rockchip,clk-out";
      reg = <0 0xfd58a000 0 0x4>;
      clocks = <&cru I2S1_8CH_MCLKOUT>;
      #clock-cells = <0>;
      clock-output-names = "i2s1m1_mclkout_to_io";
      rockchip,bit-shift = <6>;
    };

    mclkout_i2s2: mclkout-i2s2@fd58c318 {
      compatible = "rockchip,clk-out";
      reg = <0 0xfd58c318 0 0x4>;
      clocks = <&cru I2S2_2CH_MCLKOUT>;
      #clock-cells = <0>;
      clock-output-names = "i2s2_mclkout_to_io";
      power-domains = <&power RK3588_PD_AUDIO>;
      rockchip,bit-shift = <2>;
      rockchip,bit-set-to-disable;
    };

    mclkout_i2s3: mclkout-i2s3@fd58c318 {
      compatible = "rockchip,clk-out";
      reg = <0 0xfd58c318 0 0x4>;
      clocks = <&cru I2S3_2CH_MCLKOUT>;
      #clock-cells = <0>;
      clock-output-names = "i2s3_mclkout_to_io";
      power-domains = <&power RK3588_PD_AUDIO>;
      rockchip,bit-shift = <7>;
      rockchip,bit-set-to-disable;
    };
};

/* Disable old hantro-based AV1 decoder */
&av1d {
  status = "disabled";
};

/* New V4L2 stateless AV1 decoder (MPP-based architecture) */
/ {
  av1_decoder: video-codec@fdc70000 {
    compatible = "rockchip,rk3588-av1-decoder";
    reg = <0x0 0xfdc70000 0x0 0x800>,   /* VCD registers */
          <0x0 0xfdc80000 0x0 0x400>,   /* CACHE registers */
          <0x0 0xfdc90000 0x0 0x400>;   /* AFBC registers */
    reg-names = "vcd", "cache", "afbc";
    interrupts = <GIC_SPI 108 IRQ_TYPE_LEVEL_HIGH 0>,
                 <GIC_SPI 107 IRQ_TYPE_LEVEL_HIGH 0>,
                 <GIC_SPI 106 IRQ_TYPE_LEVEL_HIGH 0>;
    interrupt-names = "vdpu", "irq_cache", "irq_afbc";
    assigned-clocks = <&cru ACLK_AV1>, <&cru PCLK_AV1>;
    assigned-clock-rates = <400000000>, <400000000>;
    clocks = <&cru ACLK_AV1>, <&cru PCLK_AV1>;
    clock-names = "aclk", "hclk";
    power-domains = <&power RK3588_PD_AV1>;
    resets = <&cru SRST_A_AV1>, <&cru SRST_P_AV1>,
             <&cru SRST_A_AV1_BIU>, <&cru SRST_P_AV1_BIU>;
    iommus = <&av1d_mmu>;
    status = "okay";
  };
};

#include "rk3588s-sound.dtsi"
